# LPC176x5x register map
File version: 0.2
CPU: CM3 r0p0, little endian, MPU, no FPU, 5 interrupt priority bits
Registers are 32-bit, read-write, reset 0x0 unless marked. A register's access mark holds for its fields unless they carry their own. Offsets are from the block's base; [hi:lo] are bit positions; {n}, {i} and the like mark numbered series; 'fields as' and 'values as' point back to an identical list.

## GPDMA — General purpose DMA controller
Base 0x50004000
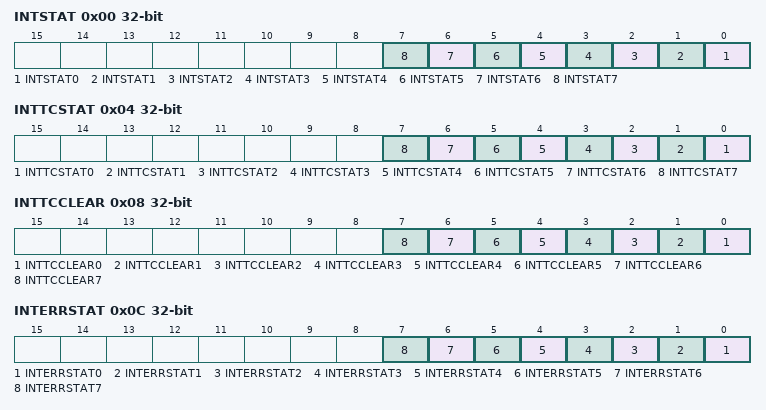
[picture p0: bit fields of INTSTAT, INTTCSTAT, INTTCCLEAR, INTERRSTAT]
0x00 INTSTAT ro — DMA Interrupt Status Register
  [n] INTSTAT{n} (n=0..7) — Status of DMA channel interrupts after masking. Each bit represents one channel: 0 - the corresponding channel has no active interrupt request. 1 - the corresponding channel does have an active interrupt request.
0x04 INTTCSTAT ro — DMA Interrupt Terminal Count Request Status Register
  [n] INTTCSTAT{n} (n=0..7) — Terminal count interrupt request status for DMA channels. Each bit represents one channel: 0 - the corresponding channel has no active terminal count interrupt request. 1 - the corresponding channel does have an active terminal count interrupt request.
0x08 INTTCCLEAR wo reset not defined — DMA Interrupt Terminal Count Request Clear Register
  [n] INTTCCLEAR{n} (n=0..7) — Allows clearing the Terminal count interrupt request (IntTCStat) for DMA channels. Each bit represents one channel: 0 - writing 0 has no effect. 1 - clears the corresponding channel terminal count interrupt.
0x0C INTERRSTAT ro — DMA Interrupt Error Status Register
  [n] INTERRSTAT{n} (n=0..7) — Interrupt error status for DMA channels. Each bit represents one channel: 0 - the corresponding channel has no active error interrupt request. 1 - the corresponding channel does have an active error interrupt request.
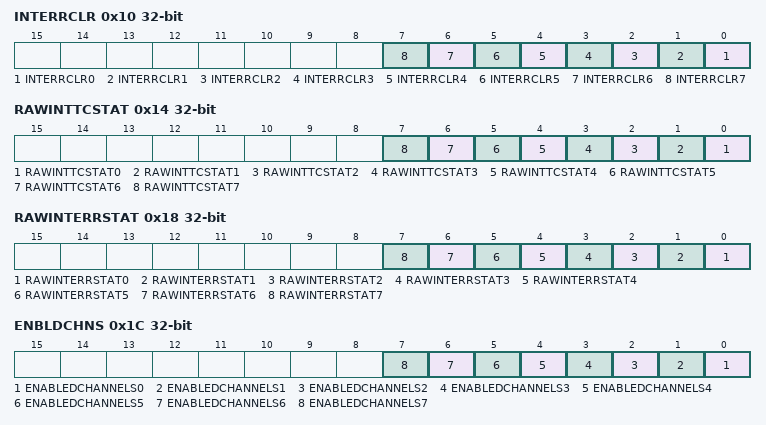
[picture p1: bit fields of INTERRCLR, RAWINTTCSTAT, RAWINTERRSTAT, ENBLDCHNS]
0x10 INTERRCLR wo reset not defined — DMA Interrupt Error Clear Register
  [n] INTERRCLR{n} (n=0..7) — Writing a 1 clears the error interrupt request (IntErrStat) for DMA channels. Each bit represents one channel: 0 - writing 0 has no effect. 1 - clears the corresponding channel error interrupt.
0x14 RAWINTTCSTAT ro — DMA Raw Interrupt Terminal Count Status Register
  [n] RAWINTTCSTAT{n} (n=0..7) — Status of the terminal count interrupt for DMA channels prior to masking. Each bit represents one channel: 0 - the corresponding channel has no active terminal count interrupt request. 1 - the corresponding channel does have an active terminal count interrupt request.
0x18 RAWINTERRSTAT ro — DMA Raw Error Interrupt Status Register
  [n] RAWINTERRSTAT{n} (n=0..7) — Status of the error interrupt for DMA channels prior to masking. Each bit represents one channel: 0 - the corresponding channel has no active error interrupt request. 1 - the corresponding channel does have an active error interrupt request.
0x1C ENBLDCHNS ro — DMA Enabled Channel Register
  [n] ENABLEDCHANNELS{n} (n=0..7) — Enable status for DMA channels. Each bit represents one channel: 0 - DMA channel is disabled. 1 - DMA channel is enabled.
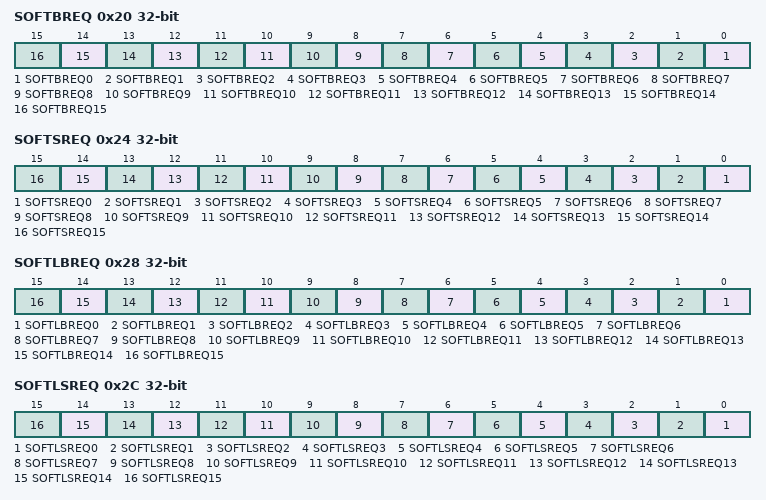
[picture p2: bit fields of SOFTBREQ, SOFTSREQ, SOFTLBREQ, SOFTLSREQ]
0x20 SOFTBREQ — DMA Software Burst Request Register
  [n] SOFTBREQ{n} (n=0..15) — Software burst request flags for each of 16 possible sources. Each bit represents one DMA request line or peripheral Description (refer to Table 672 for peripheral hardware connections to the DMA controller): 0 - writing 0 has no effect. 1 - writing 1 generates a DMA burst request for the corresponding request line.
0x24 SOFTSREQ — DMA Software Single Request Register
  [n] SOFTSREQ{n} (n=0..15) — Software single transfer request flags for each of 16 possible sources. Each bit represents one DMA request line or peripheral function: 0 - writing 0 has no effect. 1 - writing 1 generates a DMA single transfer request for the corresponding request line.
0x28 SOFTLBREQ — DMA Software Last Burst Request Register
  [n] SOFTLBREQ{n} (n=0..15) — Software last burst request flags for each of 16 possible sources. Each bit represents one DMA request line or peripheral function: 0 - writing 0 has no effect. 1 - writing 1 generates a DMA last burst request for the corresponding request line.
0x2C SOFTLSREQ — DMA Software Last Single Request Register
  [n] SOFTLSREQ{n} (n=0..15) — Software last single transfer request flags for each of 16 possible sources. Each bit represents one DMA request line or peripheral function: 0 - writing 0 has no effect. 1 - writing 1 generates a DMA last single transfer request for the corresponding request line.
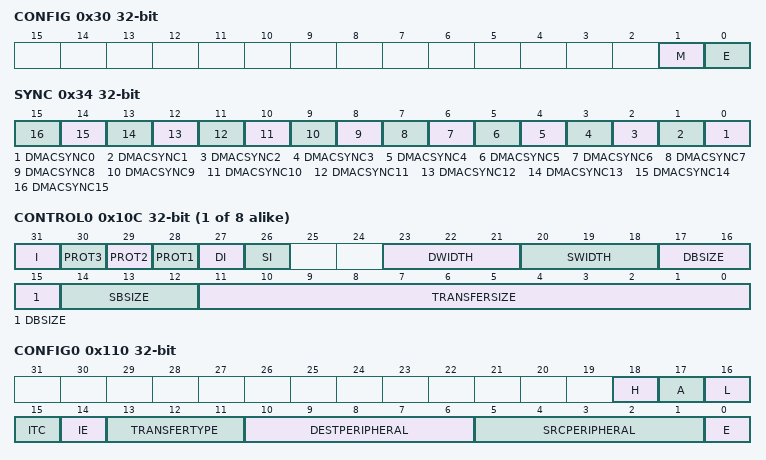
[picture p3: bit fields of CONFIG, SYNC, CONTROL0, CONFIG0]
0x30 CONFIG — DMA Configuration Register
  [1] M — AHB Master endianness configuration: 0 = little-endian mode (default). 1 = big-endian mode.
  [0] E — DMA Controller enable: 0 = disabled (default). Disabling the DMA Controller reduces power consumption. 1 = enabled.
0x34 SYNC — DMA Synchronization Register
  [n] DMACSYNC{n} (n=0..15) — Controls the synchronization logic for DMA request signals. Each bit represents one set of DMA request lines as described in the preceding text: 0 - synchronization logic for the corresponding DMA request signals are enabled. 1 - synchronization logic for the corresponding DMA request signals are disabled.
{0x100+0x20*i} SRCADDR{i} (i=0..7) — DMA Channel 0 Source Address Register
  [31:0] SRCADDR — DMA source address. Reading this register will return the current source address.
{0x104+0x20*i} DESTADDR{i} (i=0..7) — DMA Channel 0 Destination Address Register
  [31:0] DESTADDR — DMA Destination address. Reading this register will return the current destination address.
{0x108+0x20*i} LLI{i} (i=0..7) — DMA Channel 0 Linked List Item Register
  [31:2] LLI — Linked list item. Bits [31:2] of the address for the next LLI. Address bits [1:0] are 0.
{0x10C+0x20*i} CONTROL{i} (i=0..7) — DMA Channel 0 Control Register
  [31] I — Terminal count interrupt enable bit. 0 - the terminal count interrupt is disabled. 1 - the terminal count interrupt is enabled.
  [30] PROT3 — This is provided to the peripheral during a DMA bus access and indicates to the peripheral that the access is cacheable or not cacheable. This information is not used in the LPC178x/177x. 0 - access is not cacheable. 1 - access is cacheable.
  [29] PROT2 — This is provided to the peripheral during a DMA bus access and indicates to the peripheral that the access is bufferable or not bufferable. This information is not used in the LPC178x/177x. 0 - access is not bufferable. 1 - access is bufferable.
  [28] PROT1 — This is provided to the peripheral during a DMA bus access and indicates that the access is in user mode or privileged mode. This information is not used in the LPC178x/177x. 0 - access is in user mode. 1 - access is in privileged mode.
  [27] DI — Destination increment: 0 - the destination address is not incremented after each transfer. 1 - the destination address is incremented after each transfer.
  [26] SI — Source increment: 0 - the source address is not incremented after each transfer. 1 - the source address is incremented after each transfer.
  [23:21] DWIDTH — Destination transfer width. The source and destination widths can be different from each other. The hardware automatically packs and unpacks the data as required. 000 - Byte (8-bit) 001 - Halfword (16-bit) 010 - Word (32-bit) 011 to 111 - Reserved
  [20:18] SWIDTH — Source transfer width. The source and destination widths can be different from each other. The hardware automatically packs and unpacks the data as required. 000 - Byte (8-bit) 001 - Halfword (16-bit) 010 - Word (32-bit) 011 to 111 - Reserved
  [17:15] DBSIZE — Destination burst size. Indicates the number of transfers that make up a destination burst transfer request. This value must be set to the burst size of the destination peripheral or, if the destination is memory, to the memory boundary size. The burst size is the amount of data that is transferred when the DMACBREQ signal goes active in the destination peripheral. 000 - 1 001 - 4 010 - 8 011 - 16 100 - 32 101 - 64 110 - 128 111 - 256
  [14:12] SBSIZE — Source burst size. Indicates the number of transfers that make up a source burst. This value must be set to the burst size of the source peripheral, or if the source is memory, to the memory boundary size. The burst size is the amount of data that is transferred when the DMACBREQ signal goes active in the source peripheral. 000 - 1 001 - 4 010 - 8 011 - 16 100 - 32 101 - 64 110 - 128 111 - 256
  [11:0] TRANSFERSIZE — Transfer size. This field sets the size of the transfer when the DMA controller is the flow controller, in which case the value must be set before the channel is enabled. Transfer size is updated as data transfers are completed. A read from this field indicates the number of transfers completed on the destination bus. Reading the register when the channel is active does not give useful information because by the time that the software has processed the value read, the channel might have progressed. It is intended to be used only when a channel is enabled and then disabled. The transfer size value is not used if a peripheral is the flow controller.
0x110 CONFIG0 — DMA Channel 0 Configuration Register
  [18] H — Halt: 0 = enable DMA requests. 1 = ignore further source DMA requests. The contents of the channel FIFO are drained. This value can be used with the Active and Channel Enable bits to cleanly disable a DMA channel.
  [17] A — Active: 0 = there is no data in the FIFO of the channel. 1 = the channel FIFO has data. This value can be used with the Halt and Channel Enable bits to cleanly disable a DMA channel. This is a read-only bit.
  [16] L — Lock. When set, this bit enables locked transfers. This information is not used in the LPC178x/177x.
  [15] ITC — Terminal count interrupt mask. When cleared, this bit masks out the terminal count interrupt of the relevant channel.
  [14] IE — Interrupt error mask. When cleared, this bit masks out the error interrupt of the relevant channel.
  [13:11] TRANSFERTYPE — This value indicates the type of transfer and specifies the flow controller. The transfer type can be memory-to-memory, memory-to-peripheral, peripheral-to-memory, or peripheral-to-peripheral. Flow can be controlled by the DMA controller, the source peripheral, or the destination peripheral. Refer to Table 694 for the encoding of this field.
  [10:6] DESTPERIPHERAL — Destination peripheral. This value selects the DMA destination request peripheral. This field is ignored if the destination of the transfer is to memory. See Table 672 for peripheral identification.
  [5:1] SRCPERIPHERAL — Source peripheral. This value selects the DMA source request peripheral. This field is ignored if the source of the transfer is from memory. See Table 672 for peripheral identification.
  [0] E — Channel enable. Reading this bit indicates whether a channel is currently enabled or disabled: 0 = channel disabled. 1 = channel enabled. The Channel Enable bit status can also be found by reading the DMACEnbldChns Register. A channel is enabled by setting this bit. A channel can be disabled by clearing the Enable bit. This causes the current AHB transfer (if one is in progress) to complete and the channel is then disabled. Any data in the FIFO of the relevant channel is lost. Restarting the channel by setting the Channel Enable bit has unpredictable effects, the channel must be fully re-initialized. The channel is also disabled, and Channel Enable bit cleared, when the last LLI is reached, the DMA transfer is completed, or if a channel error is encountered. If a channel must be disabled without losing data in the FIFO, the Halt bit must be set so that further DMA requests are ignored. The Active bit must then be polled until it reaches 0, indicating that there is no data left in the FIFO. Finally, the Channel Enable bit can be cleared.
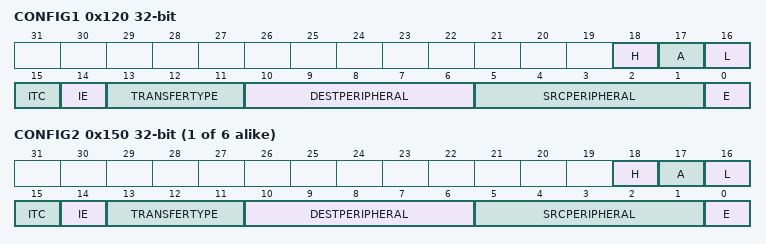
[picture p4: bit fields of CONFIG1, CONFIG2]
0x120 CONFIG1 — DMA Channel 1 Configuration Register
  fields as CONFIG0
{0x110+0x20*i} CONFIG{i} (i=2..7) — DMA Channel {i} Configuration Register
  fields as CONFIG0
